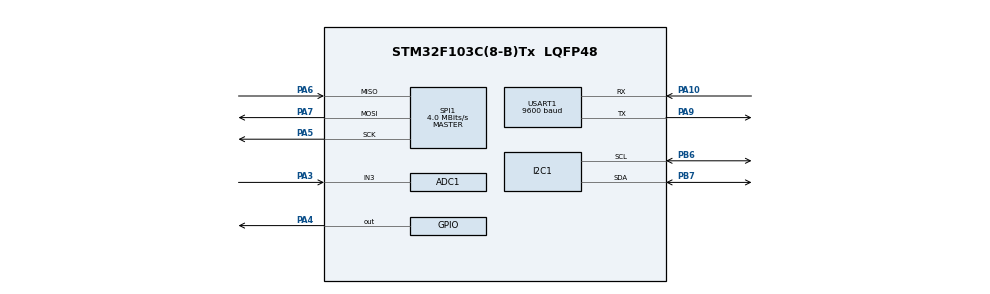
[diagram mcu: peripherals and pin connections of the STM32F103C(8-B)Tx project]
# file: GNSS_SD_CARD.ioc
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ADC1.Channel-0\#ChannelRegularConversion=ADC_CHANNEL_3
ADC1.ContinuousConvMode=ENABLE
ADC1.NbrOfConversionFlag=1
ADC1.Rank-0\#ChannelRegularConversion=1
ADC1.SamplingTime-0\#ChannelRegularConversion=ADC_SAMPLETIME_1CYCLE_5
ADC1.master=1
FATFS._MAX_SS=4096
FATFS._USE_LFN=1
I2C1.I2C_Mode=I2C_Fast
Mcu.Family=STM32F1
Mcu.Name=STM32F103C(8-B)Tx
Mcu.Package=LQFP48
NVIC.PriorityGroup=NVIC_PRIORITYGROUP_4
NVIC.USART1_IRQn=true\:0\:0\:false\:false\:true\:true\:true\:true
PA10.Mode=Asynchronous
PA10.Signal=USART1_RX
PA13.Mode=Serial_Wire
PA13.Signal=SYS_JTMS-SWDIO
PA14.Mode=Serial_Wire
PA14.Signal=SYS_JTCK-SWCLK
PA3.Signal=ADCx_IN3
PA4.GPIO_Speed=GPIO_SPEED_FREQ_HIGH
PA4.PinState=GPIO_PIN_SET
PA4.Signal=GPIO_Output
PA5.Mode=Full_Duplex_Master
PA5.Signal=SPI1_SCK
PA6.Mode=Full_Duplex_Master
PA6.Signal=SPI1_MISO
PA7.Mode=Full_Duplex_Master
PA7.Signal=SPI1_MOSI
PA9.Mode=Asynchronous
PA9.Signal=USART1_TX
PB6.Mode=I2C
PB6.Signal=I2C1_SCL
PB7.Mode=I2C
PB7.Signal=I2C1_SDA
ProjectManager.HeapSize=0x200
ProjectManager.StackSize=0x400
ProjectManager.TargetToolchain=STM32CubeIDE
RCC.APB1Freq_Value=8000000
RCC.APB2Freq_Value=8000000
SH.ADCx_IN3.0=ADC1_IN3,IN3
SPI1.BaudRatePrescaler=SPI_BAUDRATEPRESCALER_2
SPI1.CalculateBaudRate=4.0 MBits/s
SPI1.Direction=SPI_DIRECTION_2LINES
SPI1.Mode=SPI_MODE_MASTER
SPI1.VirtualType=VM_MASTER
USART1.BaudRate=9600
USART1.VirtualMode=VM_ASYNC
VP_FATFS_VS_Generic.Mode=User_defined
board=custom

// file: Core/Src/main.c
/* USER CODE BEGIN Header */
/**
  ******************************************************************************
  * @file           : main.c
  * @brief          : Main program body
  ******************************************************************************
  * @attention
  *
  * Copyright (c) 2024 STMicroelectronics.
  * All rights reserved.
  *
  * This software is licensed under terms that can be found in the LICENSE file
  * in the root directory of this software component.
  * If no LICENSE file comes with this software, it is provided AS-IS.
  *
  ******************************************************************************
  */
/* USER CODE END Header */
#include "main.h"
#include "fatfs.h"

/* USER CODE BEGIN Includes */
#include "fonts.h"
#include "ssd1306.h"
#include "aplication.h"
/* USER CODE END Includes */

//ADC_HandleTypeDef hadc1;

I2C_HandleTypeDef hi2c1;

SPI_HandleTypeDef hspi1;

//UART_HandleTypeDef huart1;

void SystemClock_Config(void);
static void MX_GPIO_Init(void);
static void MX_SPI1_Init(void);
static void MX_I2C1_Init(void);
static void MX_USART1_UART_Init(void);
static void MX_ADC1_Init(void);

int main(void)
{

  /* MCU Configuration--------------------------------------------------------*/

  /* Reset of all peripherals, Initializes the Flash interface and the Systick. */
  HAL_Init();

  /* Configure the system clock */
  SystemClock_Config();

  /* Initialize all configured peripherals */
  MX_GPIO_Init();
  MX_FATFS_Init();
  MX_SPI1_Init();
  MX_I2C1_Init();
  MX_USART1_UART_Init();
  MX_ADC1_Init();
  /* USER CODE BEGIN 2 */
  HAL_Delay(1500);
  Display.configurado = VELOCIDADE;
  initDisplay(&Display);
  HAL_UART_Receive_IT(&huart1, (uint8_t*)gnss.RxDataSerial, 1);
  HAL_ADC_Start(&hadc1);

  /* USER CODE END 2 */

  /* Infinite loop */
  /* USER CODE BEGIN WHILE */
  while (1){

	  if(gnss.indy == 0){
		  decodeNMEA(&gnss.RxDataSerial[13][0], &gnss, &tensao);
		  //gnss.velocidade.velocidade8bits = 10;//debug

	  }else{
		  decodeNMEA(&gnss.RxDataSerial[gnss.indy-1][0], &gnss, &tensao);
		  //gnss.velocidade.velocidade8bits = gnss.indy-1;//debug

	  }

	  updateDisplay(&Display,&gnss);

    /* USER CODE END WHILE */

  }
}

void SystemClock_Config(void)
{
  RCC_OscInitTypeDef RCC_OscInitStruct = {0};
  RCC_ClkInitTypeDef RCC_ClkInitStruct = {0};
  RCC_PeriphCLKInitTypeDef PeriphClkInit = {0};

  /** Initializes the RCC Oscillators according to the specified parameters
  * in the RCC_OscInitTypeDef structure.
  */
  RCC_OscInitStruct.OscillatorType = RCC_OSCILLATORTYPE_HSI;
  RCC_OscInitStruct.HSIState = RCC_HSI_ON;
  RCC_OscInitStruct.HSICalibrationValue = RCC_HSICALIBRATION_DEFAULT;
  RCC_OscInitStruct.PLL.PLLState = RCC_PLL_NONE;
  if (HAL_RCC_OscConfig(&RCC_OscInitStruct) != HAL_OK)
  {
    Error_Handler();
  }

  /** Initializes the CPU, AHB and APB buses clocks
  */
  RCC_ClkInitStruct.ClockType = RCC_CLOCKTYPE_HCLK|RCC_CLOCKTYPE_SYSCLK
                              |RCC_CLOCKTYPE_PCLK1|RCC_CLOCKTYPE_PCLK2;
  RCC_ClkInitStruct.SYSCLKSource = RCC_SYSCLKSOURCE_HSI;
  RCC_ClkInitStruct.AHBCLKDivider = RCC_SYSCLK_DIV1;
  RCC_ClkInitStruct.APB1CLKDivider = RCC_HCLK_DIV1;
  RCC_ClkInitStruct.APB2CLKDivider = RCC_HCLK_DIV1;

  if (HAL_RCC_ClockConfig(&RCC_ClkInitStruct, FLASH_LATENCY_0) != HAL_OK)
  {
    Error_Handler();
  }
  PeriphClkInit.PeriphClockSelection = RCC_PERIPHCLK_ADC;
  PeriphClkInit.AdcClockSelection = RCC_ADCPCLK2_DIV2;
  if (HAL_RCCEx_PeriphCLKConfig(&PeriphClkInit) != HAL_OK)
  {
    Error_Handler();
  }
}

static void MX_ADC1_Init(void)
{

  ADC_ChannelConfTypeDef sConfig = {0};

  /** Common config
  */
  hadc1.Instance = ADC1;
  hadc1.Init.ScanConvMode = ADC_SCAN_DISABLE;
  hadc1.Init.ContinuousConvMode = ENABLE;
  hadc1.Init.DiscontinuousConvMode = DISABLE;
  hadc1.Init.ExternalTrigConv = ADC_SOFTWARE_START;
  hadc1.Init.DataAlign = ADC_DATAALIGN_RIGHT;
  hadc1.Init.NbrOfConversion = 1;
  if (HAL_ADC_Init(&hadc1) != HAL_OK)
  {
    Error_Handler();
  }

  /** Configure Regular Channel
  */
  sConfig.Channel = ADC_CHANNEL_3;
  sConfig.Rank = ADC_REGULAR_RANK_1;
  sConfig.SamplingTime = ADC_SAMPLETIME_1CYCLE_5;
  if (HAL_ADC_ConfigChannel(&hadc1, &sConfig) != HAL_OK)
  {
    Error_Handler();
  }

}

static void MX_I2C1_Init(void)
{

  hi2c1.Instance = I2C1;
  hi2c1.Init.ClockSpeed = 400000;
  hi2c1.Init.DutyCycle = I2C_DUTYCYCLE_2;
  hi2c1.Init.OwnAddress1 = 0;
  hi2c1.Init.AddressingMode = I2C_ADDRESSINGMODE_7BIT;
  hi2c1.Init.DualAddressMode = I2C_DUALADDRESS_DISABLE;
  hi2c1.Init.OwnAddress2 = 0;
  hi2c1.Init.GeneralCallMode = I2C_GENERALCALL_DISABLE;
  hi2c1.Init.NoStretchMode = I2C_NOSTRETCH_DISABLE;
  if (HAL_I2C_Init(&hi2c1) != HAL_OK)
  {
    Error_Handler();
  }

}

static void MX_SPI1_Init(void)
{

  /* SPI1 parameter configuration*/
  hspi1.Instance = SPI1;
  hspi1.Init.Mode = SPI_MODE_MASTER;
  hspi1.Init.Direction = SPI_DIRECTION_2LINES;
  hspi1.Init.DataSize = SPI_DATASIZE_8BIT;
  hspi1.Init.CLKPolarity = SPI_POLARITY_LOW;
  hspi1.Init.CLKPhase = SPI_PHASE_1EDGE;
  hspi1.Init.NSS = SPI_NSS_SOFT;
  hspi1.Init.BaudRatePrescaler = SPI_BAUDRATEPRESCALER_2;
  hspi1.Init.FirstBit = SPI_FIRSTBIT_MSB;
  hspi1.Init.TIMode = SPI_TIMODE_DISABLE;
  hspi1.Init.CRCCalculation = SPI_CRCCALCULATION_DISABLE;
  hspi1.Init.CRCPolynomial = 10;
  if (HAL_SPI_Init(&hspi1) != HAL_OK)
  {
    Error_Handler();
  }

}

static void MX_USART1_UART_Init(void)
{

  huart1.Instance = USART1;
  huart1.Init.BaudRate = 9600;
  huart1.Init.WordLength = UART_WORDLENGTH_8B;
  huart1.Init.StopBits = UART_STOPBITS_1;
  huart1.Init.Parity = UART_PARITY_NONE;
  huart1.Init.Mode = UART_MODE_TX_RX;
  huart1.Init.HwFlowCtl = UART_HWCONTROL_NONE;
  huart1.Init.OverSampling = UART_OVERSAMPLING_16;
  if (HAL_UART_Init(&huart1) != HAL_OK)
  {
    Error_Handler();
  }

}

static void MX_GPIO_Init(void)
{
  GPIO_InitTypeDef GPIO_InitStruct = {0};

  /* GPIO Ports Clock Enable */
  __HAL_RCC_GPIOA_CLK_ENABLE();
  __HAL_RCC_GPIOB_CLK_ENABLE();

  /*Configure GPIO pin Output Level */
  HAL_GPIO_WritePin(GPIOA, GPIO_PIN_4, GPIO_PIN_SET);

  /*Configure GPIO pin : PA4 */
  GPIO_InitStruct.Pin = GPIO_PIN_4;
  GPIO_InitStruct.Mode = GPIO_MODE_OUTPUT_PP;
  GPIO_InitStruct.Pull = GPIO_NOPULL;
  GPIO_InitStruct.Speed = GPIO_SPEED_FREQ_HIGH;
  HAL_GPIO_Init(GPIOA, &GPIO_InitStruct);

}

void Error_Handler(void)
{
  __disable_irq();
  while (1)
  {
  }
}
